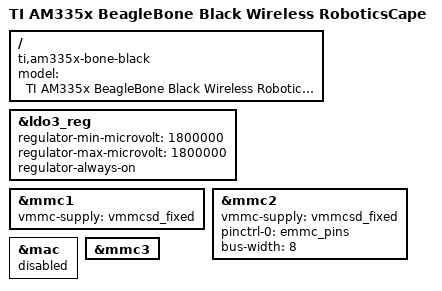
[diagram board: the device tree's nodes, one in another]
/*
 * @file am335x-boneblack-wireless-roboticscape.dtb
 *
 * based on am335x-boneblack-wireless.dtb
 *
 * This device tree serves to replace the need for an overlay when using
 * the RoboticsCape. It is similar to the boneblue tree but preserves
 * pin config for the black.
 *
 * This file was updated in April 2018 to support LED driver like in BB Blue
 * This goes in sync with V0.4.0 of the Robotics Cape library
 *
 * @author James Strawson
 * @date April 19, 2018
 */


/dts-v1/;

#include "am33xx.dtsi"
#include "am335x-bone-common-no-capemgr.dtsi"
#include "am335x-bone-common-universal-pins.dtsi"
#include "am335x-boneblack-wl1835.dtsi"
#include "am335x-roboticscape.dtsi"

/ {
	model = "TI AM335x BeagleBone Black Wireless RoboticsCape";
	compatible = "ti,am335x-bone-black", "ti,am335x-bone", "ti,am33xx";
};

&ldo3_reg {
	regulator-min-microvolt = <1800000>;
	regulator-max-microvolt = <1800000>;
	regulator-always-on;
};

&mmc1 {
	vmmc-supply = <&vmmcsd_fixed>;
};

&mmc2 {
	vmmc-supply = <&vmmcsd_fixed>;
	pinctrl-names = "default";
	pinctrl-0 = <&emmc_pins>;
	bus-width = <8>;
	status = "okay";
};

&mac {
	status = "disabled";
};

&mmc3 {
	status = "okay";
};
